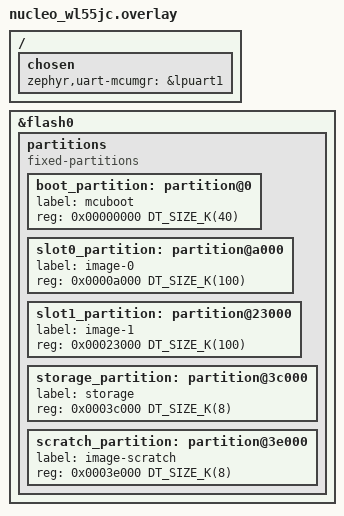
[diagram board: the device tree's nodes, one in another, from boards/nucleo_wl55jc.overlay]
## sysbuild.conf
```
# Sysbuild configuration file for FUOTA

# Enable MCUboot
SB_CONFIG_BOOTLOADER_MCUBOOT=y

# Add private key for MCUboot
SB_CONFIG_BOOT_SIGNATURE_KEY_FILE="/workdir/boot_with_keys/private_key.pem"

# Configure key type
SB_CONFIG_BOOT_SIGNATURE_TYPE_ECDSA_P256=y

# Enable multi-image mode for FUOTA (slot0 and slot1)
SB_CONFIG_MCUBOOT_MODE_SINGLE_APP=n
```

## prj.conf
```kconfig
# General Zephyr settings
CONFIG_MAIN_STACK_SIZE=2048
CONFIG_SYSTEM_WORKQUEUE_STACK_SIZE=2048
CONFIG_THREAD_NAME=n
CONFIG_LOG=y

# LoRa PHY
CONFIG_LORA=y

# NVS required to store LoRaWAN DevNonce
CONFIG_NVS=y
CONFIG_SETTINGS=y
CONFIG_SETTINGS_NVS=y

# Random number generator required for several LoRaWAN services
CONFIG_ENTROPY_GENERATOR=y

# LoRaWAN application layer
CONFIG_LORAWAN=y
CONFIG_LORAMAC_REGION_US915=y
CONFIG_LORAWAN_NVM_SETTINGS=y

# LoRaWAN services required for FUOTA
CONFIG_LORAWAN_SERVICES=y
CONFIG_LORAWAN_SERVICES_LOG_LEVEL_WRN=y
CONFIG_LORAWAN_APP_CLOCK_SYNC=y
CONFIG_LORAWAN_REMOTE_MULTICAST=y
CONFIG_LORAWAN_FRAG_TRANSPORT=y


# Flash driver to store firmware image
CONFIG_FLASH=y
CONFIG_FLASH_MAP=y
CONFIG_FLASH_PAGE_LAYOUT=y
CONFIG_STREAM_FLASH=y
CONFIG_IMG_MANAGER=y


# # Enable MCUboot support
# CONFIG_BOOTLOADER_MCUBOOT=y

# # Reboot support to switch to new image
CONFIG_REBOOT=y

# Enable mcumgr DFU in application
# Enable MCUMGR 
CONFIG_MCUMGR=y

# Enable MCUMGR management for both OS and Images
CONFIG_MCUMGR_GRP_OS=y
CONFIG_MCUMGR_GRP_IMG=y

# Configure MCUMGR transport to UART
CONFIG_MCUMGR_TRANSPORT_UART=y

# Dependencies
# Configure dependencies for CONFIG_MCUMGR  
CONFIG_NET_BUF=y
CONFIG_ZCBOR=y
CONFIG_CRC=y

# Configure dependencies for CONFIG_MCUMGR_TRANSPORT_UART 
CONFIG_BASE64=y

# MCUboot settings
CONFIG_MCUBOOT_GENERATE_UNSIGNED_IMAGE=y


# logging -------------------------------
CONFIG_SERIAL=y
CONFIG_CONSOLE=y
CONFIG_UART_CONSOLE=y
CONFIG_PRINTK=y

CONFIG_LOG=y
CONFIG_LOG_DEFAULT_LEVEL=2
CONFIG_LOG_PROCESS_THREAD=y
CONFIG_LOG_BUFFER_SIZE=1024

# Code size optimizations
CONFIG_SIZE_OPTIMIZATIONS=y
CONFIG_LOG_MODE_MINIMAL=y
CONFIG_ASSERT=n
CONFIG_NO_OPTIMIZATIONS=n

# Disable debug features to save flash
CONFIG_DEBUG=n
CONFIG_THREAD_STACK_INFO=n
CONFIG_THREAD_MONITOR=n
```

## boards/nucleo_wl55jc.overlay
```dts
/* Application overlay for FUOTA with LoRaWAN */
/ {
    chosen {
        zephyr,uart-mcumgr = &lpuart1;
    };
};

/* 
 * Flash partition layout for STM32WL55JC (256KB total flash)
 * Must match the MCUboot overlay partition layout
 * Layout: 40KB boot + 100KB slot0 + 100KB slot1 + 8KB storage + 8KB scratch = 256KB
 */
&flash0 {
    /* Delete existing partitions node to avoid conflicts */
    /delete-node/ partitions;
    
    partitions {
        compatible = "fixed-partitions";
        #address-cells = <1>;
        #size-cells = <1>;

        /* MCUboot bootloader - 40KB at base address */
        boot_partition: partition@0 {
            label = "mcuboot";
            reg = <0x00000000 DT_SIZE_K(40)>;
        };

        /* Primary application slot (slot0) - 100KB */
        slot0_partition: partition@a000 {
            label = "image-0";
            reg = <0x0000a000 DT_SIZE_K(100)>;
        };

        /* Secondary application slot (slot1) - 100KB */
        slot1_partition: partition@23000 {
            label = "image-1";
            reg = <0x00023000 DT_SIZE_K(100)>;
        };

        /* Storage for NVS (LoRaWAN settings) - 8KB */
        storage_partition: partition@3c000 {
            label = "storage";
            reg = <0x0003c000 DT_SIZE_K(8)>;
        };

        /* Scratch area for image swapping - 8KB */
        scratch_partition: partition@3e000 {
            label = "image-scratch";
            reg = <0x0003e000 DT_SIZE_K(8)>;
        };
    };
};
```

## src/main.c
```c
/*
 * LoRaWAN FUOTA sample application
 *
 * Copyright (c) 2022-2024 Libre Solar Technologies GmbH
 * Copyright (c) 2022-2024 tado GmbH
 *
 * SPDX-License-Identifier: Apache-2.0
 */

#include <zephyr/device.h>
#include <zephyr/kernel.h>
#include <zephyr/logging/log.h>
#include <zephyr/lorawan/lorawan.h>

#include <zephyr/dfu/mcuboot.h>
#include <zephyr/sys/reboot.h>

// testing printk
#include <zephyr/sys/printk.h>



LOG_MODULE_REGISTER(lorawan_fuota, CONFIG_LORAWAN_SERVICES_LOG_LEVEL);

/* Customize based on device configuration */
#define LORAWAN_DEV_EUI  { 0x70, 0xB3, 0xD5, 0x7E, 0xD0, 0x07, 0x44, 0x14 }
#define LORAWAN_JOIN_EUI { 0x00, 0x80, 0xE1, 0x15, 0x06, 0x1D, 0xA7, 0x0F }
#define LORAWAN_APP_KEY  { 0x67, 0x5B, 0x70, 0xC7, 0x84, 0x21, 0x0E, 0x11, 0x85, 0x19, 0x44, 0xD2, 0x1D, 0x43, 0xF3, 0xE6 }

#define DELAY K_SECONDS(1)

char data[] = {'u', 'p', 'd', 'a', 't', 'e', 'd', ' ', 'd', 'a', 't', 'a'};

static void downlink_info(uint8_t port, uint8_t flags, int16_t rssi, int8_t snr, uint8_t len,
			  const uint8_t *data)
{
	LOG_ERR("Received from port %d, flags %d, RSSI %ddB, SNR %ddBm", port, flags, rssi, snr);
	if (data) {
		LOG_HEXDUMP_ERR(data, len, "Payload: ");
	}
}

static void datarate_changed(enum lorawan_datarate dr)
{
	uint8_t unused, max_size;

	lorawan_get_payload_sizes(&unused, &max_size);
	LOG_ERR("New Datarate: DR %d, Max Payload %d", dr, max_size);
}

static void fuota_finished(void)
{
	LOG_ERR("FUOTA finished. Reset device to apply firmware upgrade.");

	/*
	 * In an actual application the firmware should be rebooted here if
	 * no important tasks are pending
	 */

	int rc = boot_request_upgrade(BOOT_UPGRADE_PERMANENT);
    if (rc) {
        printk("boot_request_upgrade failed: %d\n", rc);
        return;
    }

    k_msleep(100);
    sys_reboot(SYS_REBOOT_COLD);
	
}

int main(void)
{

	printk("FUOTA app booting...\n");

	const struct device *lora_dev;
	struct lorawan_join_config join_cfg;
	uint8_t dev_eui[] = LORAWAN_DEV_EUI; 
	uint8_t join_eui[] = LORAWAN_JOIN_EUI;
	uint8_t app_key[] = LORAWAN_APP_KEY;
	int ret;

	struct lorawan_downlink_cb downlink_cb = {
		.port = LW_RECV_PORT_ANY,
		.cb = downlink_info
	};

	lora_dev = DEVICE_DT_GET(DT_ALIAS(lora0));
	if (!device_is_ready(lora_dev)) {
		LOG_ERR("%s: device not ready.", lora_dev->name);
		return -ENODEV;
	}

	ret = lorawan_start();
	if (ret < 0) {
		LOG_ERR("lorawan_start failed: %d", ret);
		return ret;
	}

	lorawan_register_downlink_callback(&downlink_cb);
	lorawan_register_dr_changed_callback(datarate_changed);

	join_cfg.mode = LORAWAN_ACT_OTAA;
	join_cfg.dev_eui = dev_eui;
	join_cfg.otaa.join_eui = join_eui;
	join_cfg.otaa.app_key = app_key;
	join_cfg.otaa.nwk_key = app_key;

	LOG_ERR("Joining network over OTAA");
	ret = lorawan_join(&join_cfg);
	if (ret < 0) {
		LOG_ERR("lorawan_join_network failed: %d", ret);
		return ret;
	}

	lorawan_enable_adr(true);

	/*
	 * Clock synchronization is required to schedule the multicast session
	 * in class C mode. It can also be used independent of FUOTA.
	 */
	lorawan_clock_sync_run();

	/*
	 * The multicast session setup service is automatically started in the
	 * background. It is also responsible for switching to class C at a
	 * specified time.
	 */

	/*
	 * The fragmented data transport transfers the actual firmware image.
	 * It could also be used in a class A session, but would take very long
	 * in that case.
	 */
	lorawan_frag_transport_run(fuota_finished);

	/*
	 * Regular uplinks are required to open downlink slots in class A for
	 * FUOTA setup by the server.
	 */
	while (1) {
		ret = lorawan_send(2, data, sizeof(data), LORAWAN_MSG_UNCONFIRMED);

		if (ret == 0) {
			LOG_ERR("Updated sent!");
		} else {
			LOG_ERR("lorawan_send failed: %d", ret);
		}

		k_sleep(DELAY);
	}

	return 0;
}
```
